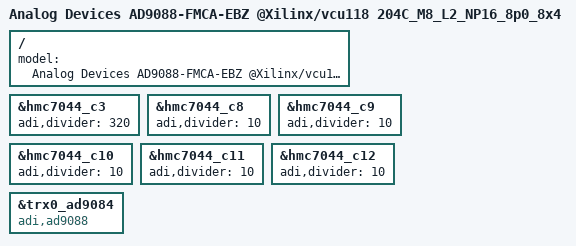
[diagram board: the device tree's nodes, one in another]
// SPDX-License-Identifier: GPL-2.0
/*
 * Analog Devices AD9088 8T8R
 * https://analogdevicesinc.github.io/linux/drivers/iio-trx-rf/ad9088/
 * https://analogdevicesinc.github.io/system-level/solutions/reference-designs/ad9084_ebz/user-guide/
 *
 * hdl_project: <ad9084_ebz/vcu118>
 * board_revision: <Rev.C>
 *
 * Copyright (C) 2026 Analog Devices Inc.
 */

#define DEVICE_PROFILE_NAME	"204C_8T8R_M8_L2_NP16_8p0_4x8.bin"

#define HMC7044_PLL2_FREQ	(2500000000) // 2.5 GHz (2150...3200 MHz range)
#define AION_VCO_FREQ_HZ	(2500000000) // 2.5 GHz (2375...2625 MHz range)

#define SYSREF_CLK_MHz		(7812500) // HMC7044_PLL2_FREQ / 320

#define OUT_CLK_SELECT		XCVR_PROGDIV_CLK
#define SYS_CLK_SELECT		XCVR_QPLL1

#define WITH_AION 1
#define WITH_AXI_AION_TRIG 0
#define ASYNM_A_B_MODE 1

#include "vcu118_ad9084.dts"

/ {
	model = "Analog Devices AD9088-FMCA-EBZ @Xilinx/vcu118 204C_M8_L2_NP16_8p0_8x4";
};

&hmc7044_c3 {
	adi,divider = <320>; /* 320 for 250 MHz */
};

&hmc7044_c8 {
	adi,divider = <10>;
};

&hmc7044_c9 {
	adi,divider = <10>;
};

&hmc7044_c10 {
	adi,divider = <10>;
};

&hmc7044_c11 {
	adi,divider = <10>;
};

&hmc7044_c12 {
	adi,divider = <10>;
};

&trx0_ad9084 {
	compatible = "adi,ad9088";
};
